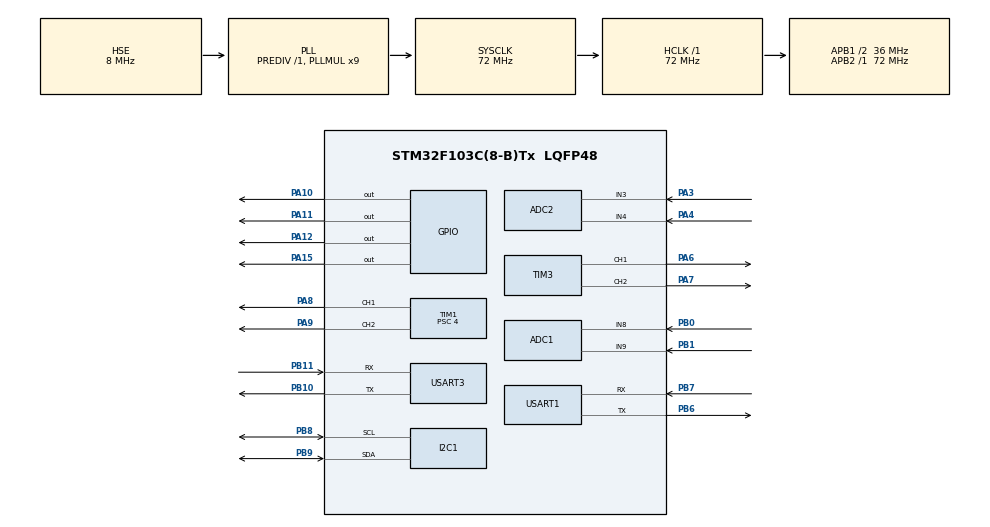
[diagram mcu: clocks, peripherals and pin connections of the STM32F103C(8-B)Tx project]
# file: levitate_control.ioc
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ADC1.Channel-1\#ChannelRegularConversion=ADC_CHANNEL_8
ADC1.NbrOfConversionFlag=1
ADC1.Rank-1\#ChannelRegularConversion=1
ADC1.SamplingTime-1\#ChannelRegularConversion=ADC_SAMPLETIME_1CYCLE_5
ADC1.master=1
ADC2.Channel-1\#ChannelRegularConversion=ADC_CHANNEL_3
ADC2.NbrOfConversionFlag=1
ADC2.Rank-1\#ChannelRegularConversion=1
ADC2.SamplingTime-1\#ChannelRegularConversion=ADC_SAMPLETIME_1CYCLE_5
FREERTOS.HEAP_NUMBER=3
FREERTOS.INCLUDE_vTaskDelayUntil=1
FREERTOS.MEMORY_ALLOCATION=0
FREERTOS.Tasks01=defaultTask,0,128,StartDefaultTask,Default,NULL,Dynamic,NULL,NULL
FREERTOS.configTOTAL_HEAP_SIZE=4096
Mcu.Family=STM32F1
Mcu.Name=STM32F103C(8-B)Tx
Mcu.Package=LQFP48
NVIC.PriorityGroup=NVIC_PRIORITYGROUP_4
NVIC.TIM4_IRQn=true\:0\:0\:false\:false\:true\:false\:false\:true
NVIC.TimeBase=TIM4_IRQn
NVIC.TimeBaseIP=TIM4
PA10.GPIO_PuPd=GPIO_PULLDOWN
PA10.GPIO_Speed=GPIO_SPEED_FREQ_MEDIUM
PA10.Signal=GPIO_Output
PA11.GPIO_PuPd=GPIO_PULLDOWN
PA11.GPIO_Speed=GPIO_SPEED_FREQ_MEDIUM
PA11.Signal=GPIO_Output
PA12.GPIO_PuPd=GPIO_PULLDOWN
PA12.GPIO_Speed=GPIO_SPEED_FREQ_MEDIUM
PA12.Signal=GPIO_Output
PA13.Mode=Serial_Wire
PA13.Signal=SYS_JTMS-SWDIO
PA14.Mode=Serial_Wire
PA14.Signal=SYS_JTCK-SWCLK
PA15.GPIO_PuPd=GPIO_PULLDOWN
PA15.GPIO_Speed=GPIO_SPEED_FREQ_MEDIUM
PA15.Signal=GPIO_Output
PA3.Signal=ADCx_IN3
PA4.Signal=ADCx_IN4
PA6.Signal=S_TIM3_CH1
PA7.Signal=S_TIM3_CH2
PA8.Signal=S_TIM1_CH1
PA9.Signal=S_TIM1_CH2
PB0.Signal=ADCx_IN8
PB1.Signal=ADCx_IN9
PB10.Mode=Asynchronous
PB10.Signal=USART3_TX
PB11.Mode=Asynchronous
PB11.Signal=USART3_RX
PB6.Mode=IrDA
PB6.Signal=USART1_TX
PB7.Mode=IrDA
PB7.Signal=USART1_RX
PB8.Mode=I2C
PB8.Signal=I2C1_SCL
PB9.Mode=I2C
PB9.Signal=I2C1_SDA
PD0-OSC_IN.Mode=HSE-External-Oscillator
PD0-OSC_IN.Signal=RCC_OSC_IN
PD1-OSC_OUT.Mode=HSE-External-Oscillator
PD1-OSC_OUT.Signal=RCC_OSC_OUT
ProjectManager.HeapSize=0x800
ProjectManager.StackSize=0x1000
ProjectManager.TargetToolchain=MDK-ARM V5
RCC.ADCPresc=RCC_ADCPCLK2_DIV6
RCC.AHBFreq_Value=72000000
RCC.APB1CLKDivider=RCC_HCLK_DIV2
RCC.APB1Freq_Value=36000000
RCC.APB1TimFreq_Value=72000000
RCC.APB2Freq_Value=72000000
RCC.APB2TimFreq_Value=72000000
RCC.HCLKFreq_Value=72000000
RCC.PLLMUL=RCC_PLL_MUL9
RCC.PLLSourceVirtual=RCC_PLLSOURCE_HSE
RCC.SYSCLKFreq_VALUE=72000000
RCC.SYSCLKSource=RCC_SYSCLKSOURCE_PLLCLK
RCC.USBFreq_Value=72000000
RTC.Date=15
RTC.Hours=20
RTC.Minutes=30
RTC.Seconds=35
RTC.Year=19
SH.ADCx_IN3.0=ADC2_IN3,IN3
SH.ADCx_IN4.0=ADC2_IN4,IN4
SH.ADCx_IN8.0=ADC1_IN8,IN8
SH.ADCx_IN9.0=ADC1_IN9,IN9
SH.S_TIM1_CH1.0=TIM1_CH1,PWM Generation1 CH1
SH.S_TIM1_CH2.0=TIM1_CH2,PWM Generation2 CH2
SH.S_TIM3_CH1.0=TIM3_CH1,PWM Generation1 CH1
SH.S_TIM3_CH2.0=TIM3_CH2,PWM Generation2 CH2
TIM1.Channel-PWM\ Generation1\ CH1=TIM_CHANNEL_1
TIM1.Channel-PWM\ Generation2\ CH2=TIM_CHANNEL_2
TIM1.Period=1500
TIM1.Prescaler=4
TIM3.Channel-PWM\ Generation1\ CH1=TIM_CHANNEL_1
TIM3.Channel-PWM\ Generation2\ CH2=TIM_CHANNEL_2
USART1.VirtualMode=VM_IRDA
USART3.VirtualMode=VM_ASYNC
VP_FREERTOS_VS_CMSIS_V1.Mode=CMSIS_V1
VP_RTC_VS_RTC_Activate.Mode=RTC_Enabled
VP_RTC_VS_RTC_Calendar.Mode=RTC_Calendar
VP_SYS_VS_tim4.Mode=TIM4
board=custom

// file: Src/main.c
/* USER CODE BEGIN Header */
/**
  ******************************************************************************
  * @file           : main.c
  * @brief          : Main program body
  ******************************************************************************
  * @attention
  *
  * <h2><center>&copy; Copyright (c) 2019 STMicroelectronics.
  * All rights reserved.</center></h2>
  *
  * This software component is licensed by ST under BSD 3-Clause license,
  * the "License"; You may not use this file except in compliance with the
  * License. You may obtain a copy of the License at:
  *                        opensource.org/licenses/BSD-3-Clause
  *
  ******************************************************************************
  */
/* USER CODE END Header */

#include "main.h"
#include "cmsis_os.h"

/* USER CODE BEGIN Includes */
#include "user_tasks.h"
/* USER CODE END Includes */

ADC_HandleTypeDef hadc1;
ADC_HandleTypeDef hadc2;

I2C_HandleTypeDef hi2c1;

RTC_HandleTypeDef hrtc;

TIM_HandleTypeDef htim1;
TIM_HandleTypeDef htim3;

IRDA_HandleTypeDef hirda1;
UART_HandleTypeDef huart3;

osThreadId defaultTaskHandle;

void SystemClock_Config(void);
static void MX_GPIO_Init(void);
static void MX_ADC1_Init(void);
static void MX_ADC2_Init(void);
static void MX_I2C1_Init(void);
static void MX_TIM1_Init(void);
static void MX_USART1_IRDA_Init(void);
static void MX_USART3_UART_Init(void);
static void MX_RTC_Init(void);
static void MX_TIM3_Init(void);
void StartDefaultTask(void const * argument);

int main(void)
{

  /* MCU Configuration--------------------------------------------------------*/

  /* Reset of all peripherals, Initializes the Flash interface and the Systick. */
  HAL_Init();

  /* Configure the system clock */
  SystemClock_Config();

  /* Initialize all configured peripherals */
  MX_GPIO_Init();
  MX_ADC1_Init();
  MX_ADC2_Init();
  MX_I2C1_Init();
  MX_TIM1_Init();
  MX_USART1_IRDA_Init();
  MX_USART3_UART_Init();
  MX_RTC_Init();
  MX_TIM3_Init();

  /* Create the thread(s) */
  /* definition and creation of defaultTask */
  osThreadDef(defaultTask, StartDefaultTask, osPriorityNormal, 0, 128);
  defaultTaskHandle = osThreadCreate(osThread(defaultTask), NULL);

  /* USER CODE BEGIN RTOS_THREADS */
  initTasks();
  /* USER CODE END RTOS_THREADS */

  /* Start scheduler */
  osKernelStart();

  /* We should never get here as control is now taken by the scheduler */

  /* Infinite loop */
  while (1)
  {

  }
}

void SystemClock_Config(void)
{
  RCC_OscInitTypeDef RCC_OscInitStruct = {0};
  RCC_ClkInitTypeDef RCC_ClkInitStruct = {0};
  RCC_PeriphCLKInitTypeDef PeriphClkInit = {0};

  /** Initializes the CPU, AHB and APB busses clocks
  */
  RCC_OscInitStruct.OscillatorType = RCC_OSCILLATORTYPE_LSI|RCC_OSCILLATORTYPE_HSE;
  RCC_OscInitStruct.HSEState = RCC_HSE_ON;
  RCC_OscInitStruct.HSEPredivValue = RCC_HSE_PREDIV_DIV1;
  RCC_OscInitStruct.HSIState = RCC_HSI_ON;
  RCC_OscInitStruct.LSIState = RCC_LSI_ON;
  RCC_OscInitStruct.PLL.PLLState = RCC_PLL_ON;
  RCC_OscInitStruct.PLL.PLLSource = RCC_PLLSOURCE_HSE;
  RCC_OscInitStruct.PLL.PLLMUL = RCC_PLL_MUL9;
  if (HAL_RCC_OscConfig(&RCC_OscInitStruct) != HAL_OK)
  {
    Error_Handler();
  }
  /** Initializes the CPU, AHB and APB busses clocks
  */
  RCC_ClkInitStruct.ClockType = RCC_CLOCKTYPE_HCLK|RCC_CLOCKTYPE_SYSCLK
                              |RCC_CLOCKTYPE_PCLK1|RCC_CLOCKTYPE_PCLK2;
  RCC_ClkInitStruct.SYSCLKSource = RCC_SYSCLKSOURCE_PLLCLK;
  RCC_ClkInitStruct.AHBCLKDivider = RCC_SYSCLK_DIV1;
  RCC_ClkInitStruct.APB1CLKDivider = RCC_HCLK_DIV2;
  RCC_ClkInitStruct.APB2CLKDivider = RCC_HCLK_DIV1;

  if (HAL_RCC_ClockConfig(&RCC_ClkInitStruct, FLASH_LATENCY_2) != HAL_OK)
  {
    Error_Handler();
  }
  PeriphClkInit.PeriphClockSelection = RCC_PERIPHCLK_RTC|RCC_PERIPHCLK_ADC;
  PeriphClkInit.RTCClockSelection = RCC_RTCCLKSOURCE_LSI;
  PeriphClkInit.AdcClockSelection = RCC_ADCPCLK2_DIV6;
  if (HAL_RCCEx_PeriphCLKConfig(&PeriphClkInit) != HAL_OK)
  {
    Error_Handler();
  }
}

static void MX_ADC1_Init(void)
{

  ADC_ChannelConfTypeDef sConfig = {0};

  /** Common config
  */
  hadc1.Instance = ADC1;
  hadc1.Init.ScanConvMode = ADC_SCAN_DISABLE;
  hadc1.Init.ContinuousConvMode = DISABLE;
  hadc1.Init.DiscontinuousConvMode = DISABLE;
  hadc1.Init.ExternalTrigConv = ADC_SOFTWARE_START;
  hadc1.Init.DataAlign = ADC_DATAALIGN_RIGHT;
  hadc1.Init.NbrOfConversion = 1;
  if (HAL_ADC_Init(&hadc1) != HAL_OK)
  {
    Error_Handler();
  }
  /** Configure Regular Channel
  */
  sConfig.Channel = ADC_CHANNEL_8;
  sConfig.Rank = ADC_REGULAR_RANK_1;
  sConfig.SamplingTime = ADC_SAMPLETIME_1CYCLE_5;
  if (HAL_ADC_ConfigChannel(&hadc1, &sConfig) != HAL_OK)
  {
    Error_Handler();
  }

}

static void MX_ADC2_Init(void)
{

  ADC_ChannelConfTypeDef sConfig = {0};

  /** Common config
  */
  hadc2.Instance = ADC2;
  hadc2.Init.ScanConvMode = ADC_SCAN_DISABLE;
  hadc2.Init.ContinuousConvMode = DISABLE;
  hadc2.Init.DiscontinuousConvMode = DISABLE;
  hadc2.Init.ExternalTrigConv = ADC_SOFTWARE_START;
  hadc2.Init.DataAlign = ADC_DATAALIGN_RIGHT;
  hadc2.Init.NbrOfConversion = 1;
  if (HAL_ADC_Init(&hadc2) != HAL_OK)
  {
    Error_Handler();
  }
  /** Configure Regular Channel
  */
  sConfig.Channel = ADC_CHANNEL_3;
  sConfig.Rank = ADC_REGULAR_RANK_1;
  sConfig.SamplingTime = ADC_SAMPLETIME_1CYCLE_5;
  if (HAL_ADC_ConfigChannel(&hadc2, &sConfig) != HAL_OK)
  {
    Error_Handler();
  }

}

static void MX_I2C1_Init(void)
{

  hi2c1.Instance = I2C1;
  hi2c1.Init.ClockSpeed = 100000;
  hi2c1.Init.DutyCycle = I2C_DUTYCYCLE_2;
  hi2c1.Init.OwnAddress1 = 0;
  hi2c1.Init.AddressingMode = I2C_ADDRESSINGMODE_7BIT;
  hi2c1.Init.DualAddressMode = I2C_DUALADDRESS_DISABLE;
  hi2c1.Init.OwnAddress2 = 0;
  hi2c1.Init.GeneralCallMode = I2C_GENERALCALL_DISABLE;
  hi2c1.Init.NoStretchMode = I2C_NOSTRETCH_DISABLE;
  if (HAL_I2C_Init(&hi2c1) != HAL_OK)
  {
    Error_Handler();
  }

}

static void MX_RTC_Init(void)
{

  RTC_TimeTypeDef sTime = {0};
  RTC_DateTypeDef DateToUpdate = {0};

  /** Initialize RTC Only
  */
  hrtc.Instance = RTC;
  hrtc.Init.AsynchPrediv = RTC_AUTO_1_SECOND;
  hrtc.Init.OutPut = RTC_OUTPUTSOURCE_ALARM;
  if (HAL_RTC_Init(&hrtc) != HAL_OK)
  {
    Error_Handler();
  }

  /** Initialize RTC and set the Time and Date
  */
  sTime.Hours = 0x20;
  sTime.Minutes = 0x30;
  sTime.Seconds = 0x35;

  if (HAL_RTC_SetTime(&hrtc, &sTime, RTC_FORMAT_BCD) != HAL_OK)
  {
    Error_Handler();
  }
  DateToUpdate.WeekDay = RTC_WEEKDAY_MONDAY;
  DateToUpdate.Month = RTC_MONTH_JANUARY;
  DateToUpdate.Date = 0x15;
  DateToUpdate.Year = 0x19;

  if (HAL_RTC_SetDate(&hrtc, &DateToUpdate, RTC_FORMAT_BCD) != HAL_OK)
  {
    Error_Handler();
  }

}

static void MX_TIM1_Init(void)
{

  TIM_MasterConfigTypeDef sMasterConfig = {0};
  TIM_OC_InitTypeDef sConfigOC = {0};
  TIM_BreakDeadTimeConfigTypeDef sBreakDeadTimeConfig = {0};

  htim1.Instance = TIM1;
  htim1.Init.Prescaler = 4;
  htim1.Init.CounterMode = TIM_COUNTERMODE_UP;
  htim1.Init.Period = 1500;
  htim1.Init.ClockDivision = TIM_CLOCKDIVISION_DIV1;
  htim1.Init.RepetitionCounter = 0;
  htim1.Init.AutoReloadPreload = TIM_AUTORELOAD_PRELOAD_DISABLE;
  if (HAL_TIM_PWM_Init(&htim1) != HAL_OK)
  {
    Error_Handler();
  }
  sMasterConfig.MasterOutputTrigger = TIM_TRGO_RESET;
  sMasterConfig.MasterSlaveMode = TIM_MASTERSLAVEMODE_DISABLE;
  if (HAL_TIMEx_MasterConfigSynchronization(&htim1, &sMasterConfig) != HAL_OK)
  {
    Error_Handler();
  }
  sConfigOC.OCMode = TIM_OCMODE_PWM1;
  sConfigOC.Pulse = 0;
  sConfigOC.OCPolarity = TIM_OCPOLARITY_HIGH;
  sConfigOC.OCNPolarity = TIM_OCNPOLARITY_HIGH;
  sConfigOC.OCFastMode = TIM_OCFAST_DISABLE;
  sConfigOC.OCIdleState = TIM_OCIDLESTATE_RESET;
  sConfigOC.OCNIdleState = TIM_OCNIDLESTATE_RESET;
  if (HAL_TIM_PWM_ConfigChannel(&htim1, &sConfigOC, TIM_CHANNEL_1) != HAL_OK)
  {
    Error_Handler();
  }
  if (HAL_TIM_PWM_ConfigChannel(&htim1, &sConfigOC, TIM_CHANNEL_2) != HAL_OK)
  {
    Error_Handler();
  }
  sBreakDeadTimeConfig.OffStateRunMode = TIM_OSSR_DISABLE;
  sBreakDeadTimeConfig.OffStateIDLEMode = TIM_OSSI_DISABLE;
  sBreakDeadTimeConfig.LockLevel = TIM_LOCKLEVEL_OFF;
  sBreakDeadTimeConfig.DeadTime = 0;
  sBreakDeadTimeConfig.BreakState = TIM_BREAK_DISABLE;
  sBreakDeadTimeConfig.BreakPolarity = TIM_BREAKPOLARITY_HIGH;
  sBreakDeadTimeConfig.AutomaticOutput = TIM_AUTOMATICOUTPUT_DISABLE;
  if (HAL_TIMEx_ConfigBreakDeadTime(&htim1, &sBreakDeadTimeConfig) != HAL_OK)
  {
    Error_Handler();
  }
  HAL_TIM_MspPostInit(&htim1);

}

static void MX_TIM3_Init(void)
{

  TIM_MasterConfigTypeDef sMasterConfig = {0};
  TIM_OC_InitTypeDef sConfigOC = {0};

  htim3.Instance = TIM3;
  htim3.Init.Prescaler = 0;
  htim3.Init.CounterMode = TIM_COUNTERMODE_UP;
  htim3.Init.Period = 0;
  htim3.Init.ClockDivision = TIM_CLOCKDIVISION_DIV1;
  htim3.Init.AutoReloadPreload = TIM_AUTORELOAD_PRELOAD_DISABLE;
  if (HAL_TIM_PWM_Init(&htim3) != HAL_OK)
  {
    Error_Handler();
  }
  sMasterConfig.MasterOutputTrigger = TIM_TRGO_RESET;
  sMasterConfig.MasterSlaveMode = TIM_MASTERSLAVEMODE_DISABLE;
  if (HAL_TIMEx_MasterConfigSynchronization(&htim3, &sMasterConfig) != HAL_OK)
  {
    Error_Handler();
  }
  sConfigOC.OCMode = TIM_OCMODE_PWM1;
  sConfigOC.Pulse = 0;
  sConfigOC.OCPolarity = TIM_OCPOLARITY_HIGH;
  sConfigOC.OCFastMode = TIM_OCFAST_DISABLE;
  if (HAL_TIM_PWM_ConfigChannel(&htim3, &sConfigOC, TIM_CHANNEL_1) != HAL_OK)
  {
    Error_Handler();
  }
  if (HAL_TIM_PWM_ConfigChannel(&htim3, &sConfigOC, TIM_CHANNEL_2) != HAL_OK)
  {
    Error_Handler();
  }
  HAL_TIM_MspPostInit(&htim3);

}

static void MX_USART1_IRDA_Init(void)
{

  hirda1.Instance = USART1;
  hirda1.Init.BaudRate = 115200;
  hirda1.Init.WordLength = IRDA_WORDLENGTH_8B;
  hirda1.Init.Parity = IRDA_PARITY_NONE;
  hirda1.Init.Mode = IRDA_MODE_TX_RX;
  hirda1.Init.Prescaler = 1;
  hirda1.Init.IrDAMode = IRDA_POWERMODE_NORMAL;
  if (HAL_IRDA_Init(&hirda1) != HAL_OK)
  {
    Error_Handler();
  }

}

static void MX_USART3_UART_Init(void)
{

  huart3.Instance = USART3;
  huart3.Init.BaudRate = 115200;
  huart3.Init.WordLength = UART_WORDLENGTH_8B;
  huart3.Init.StopBits = UART_STOPBITS_1;
  huart3.Init.Parity = UART_PARITY_NONE;
  huart3.Init.Mode = UART_MODE_TX_RX;
  huart3.Init.HwFlowCtl = UART_HWCONTROL_NONE;
  huart3.Init.OverSampling = UART_OVERSAMPLING_16;
  if (HAL_UART_Init(&huart3) != HAL_OK)
  {
    Error_Handler();
  }

}

static void MX_GPIO_Init(void)
{
  GPIO_InitTypeDef GPIO_InitStruct = {0};

  /* GPIO Ports Clock Enable */
  __HAL_RCC_GPIOD_CLK_ENABLE();
  __HAL_RCC_GPIOA_CLK_ENABLE();
  __HAL_RCC_GPIOB_CLK_ENABLE();

  /*Configure GPIO pin Output Level */
  HAL_GPIO_WritePin(GPIOA, GPIO_PIN_10|GPIO_PIN_11|GPIO_PIN_12|GPIO_PIN_15|GPIO_PIN_5, GPIO_PIN_RESET);

  /*Configure GPIO pins : PA10 PA11 PA12 PA15 */
  GPIO_InitStruct.Pin = GPIO_PIN_10|GPIO_PIN_11|GPIO_PIN_12|GPIO_PIN_15|GPIO_PIN_5;
  GPIO_InitStruct.Mode = GPIO_MODE_OUTPUT_PP;
  GPIO_InitStruct.Pull = GPIO_PULLDOWN;
  GPIO_InitStruct.Speed = GPIO_SPEED_FREQ_MEDIUM;
  HAL_GPIO_Init(GPIOA, &GPIO_InitStruct);

}

void StartDefaultTask(void const * argument)
{

  for(;;)
  {
    osDelay(1);
  }
}

void HAL_TIM_PeriodElapsedCallback(TIM_HandleTypeDef *htim)
{
  if (htim->Instance == TIM4) {
    HAL_IncTick();
  }
}

void Error_Handler(void)
{
}

/************************ (C) COPYRIGHT STMicroelectronics *****END OF FILE****/
